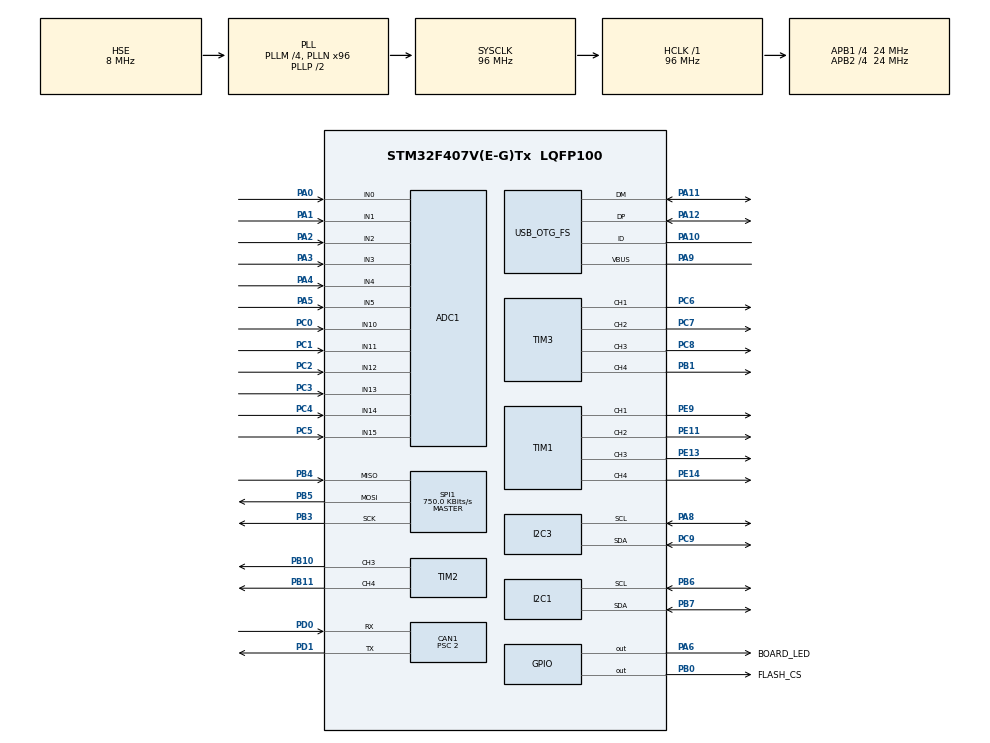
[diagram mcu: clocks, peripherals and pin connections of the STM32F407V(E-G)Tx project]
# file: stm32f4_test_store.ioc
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ADC1.Channel-0\#ChannelRegularConversion=ADC_CHANNEL_0
ADC1.Channel-1\#ChannelRegularConversion=ADC_CHANNEL_0
ADC1.Channel-10\#ChannelRegularConversion=ADC_CHANNEL_0
ADC1.Channel-11\#ChannelRegularConversion=ADC_CHANNEL_0
ADC1.Channel-2\#ChannelRegularConversion=ADC_CHANNEL_0
ADC1.Channel-3\#ChannelRegularConversion=ADC_CHANNEL_0
ADC1.Channel-4\#ChannelRegularConversion=ADC_CHANNEL_0
ADC1.Channel-5\#ChannelRegularConversion=ADC_CHANNEL_0
ADC1.Channel-6\#ChannelRegularConversion=ADC_CHANNEL_0
ADC1.Channel-7\#ChannelRegularConversion=ADC_CHANNEL_0
ADC1.Channel-8\#ChannelRegularConversion=ADC_CHANNEL_0
ADC1.Channel-9\#ChannelRegularConversion=ADC_CHANNEL_0
ADC1.NbrOfConversion=12
ADC1.NbrOfConversionFlag=1
ADC1.Rank-0\#ChannelRegularConversion=1
ADC1.Rank-1\#ChannelRegularConversion=2
ADC1.Rank-10\#ChannelRegularConversion=11
ADC1.Rank-11\#ChannelRegularConversion=12
ADC1.Rank-2\#ChannelRegularConversion=3
ADC1.Rank-3\#ChannelRegularConversion=4
ADC1.Rank-4\#ChannelRegularConversion=5
ADC1.Rank-5\#ChannelRegularConversion=6
ADC1.Rank-6\#ChannelRegularConversion=7
ADC1.Rank-7\#ChannelRegularConversion=8
ADC1.Rank-8\#ChannelRegularConversion=9
ADC1.Rank-9\#ChannelRegularConversion=10
ADC1.SamplingTime-0\#ChannelRegularConversion=ADC_SAMPLETIME_3CYCLES
ADC1.SamplingTime-1\#ChannelRegularConversion=ADC_SAMPLETIME_3CYCLES
ADC1.SamplingTime-10\#ChannelRegularConversion=ADC_SAMPLETIME_3CYCLES
ADC1.SamplingTime-11\#ChannelRegularConversion=ADC_SAMPLETIME_3CYCLES
ADC1.SamplingTime-2\#ChannelRegularConversion=ADC_SAMPLETIME_3CYCLES
ADC1.SamplingTime-3\#ChannelRegularConversion=ADC_SAMPLETIME_3CYCLES
ADC1.SamplingTime-4\#ChannelRegularConversion=ADC_SAMPLETIME_3CYCLES
ADC1.SamplingTime-5\#ChannelRegularConversion=ADC_SAMPLETIME_3CYCLES
ADC1.SamplingTime-6\#ChannelRegularConversion=ADC_SAMPLETIME_3CYCLES
ADC1.SamplingTime-7\#ChannelRegularConversion=ADC_SAMPLETIME_3CYCLES
ADC1.SamplingTime-8\#ChannelRegularConversion=ADC_SAMPLETIME_3CYCLES
ADC1.SamplingTime-9\#ChannelRegularConversion=ADC_SAMPLETIME_3CYCLES
ADC1.master=1
CAN1.ABOM=ENABLE
CAN1.BS1=CAN_BS1_10TQ
CAN1.CalculateBaudRate=1000000
CAN1.CalculateTimeBit=1000
CAN1.CalculateTimeQuantum=83.33333333333333
CAN1.NART=ENABLE
CAN1.Prescaler=2
FREERTOS.HEAP_NUMBER=1
FREERTOS.INCLUDE_uxTaskPriorityGet=0
FREERTOS.INCLUDE_vTaskDelayUntil=1
FREERTOS.INCLUDE_vTaskDelete=0
FREERTOS.INCLUDE_vTaskPrioritySet=0
FREERTOS.INCLUDE_vTaskSuspend=0
FREERTOS.MEMORY_ALLOCATION=1
FREERTOS.Tasks01=oamTask,-2,128,StartOamTask,As weak,NULL,Static,oamTaskBuffer,oamTaskControlBlock
FREERTOS.configENABLE_FPU=0
FREERTOS.configIDLE_SHOULD_YIELD=0
FREERTOS.configTOTAL_HEAP_SIZE=1024
FREERTOS.configUSE_MUTEXES=0
FREERTOS.configUSE_NEWLIB_REENTRANT=0
FREERTOS.copyHeapFile=0
Mcu.Family=STM32F4
Mcu.Name=STM32F407V(E-G)Tx
Mcu.Package=LQFP100
NVIC.PriorityGroup=NVIC_PRIORITYGROUP_4
NVIC.TIM7_IRQn=true\:15\:0\:false\:false\:true\:false\:false\:true\:true
NVIC.TimeBase=TIM7_IRQn
NVIC.TimeBaseIP=TIM7
PA0-WKUP.Signal=ADCx_IN0
PA1.Signal=ADCx_IN1
PA10.Mode=OTG/Dual_Role_Device
PA10.Signal=USB_OTG_FS_ID
PA11.Mode=OTG/Dual_Role_Device
PA11.Signal=USB_OTG_FS_DM
PA12.Mode=OTG/Dual_Role_Device
PA12.Signal=USB_OTG_FS_DP
PA13.Mode=Serial_Wire
PA13.Signal=SYS_JTMS-SWDIO
PA14.Mode=Serial_Wire
PA14.Signal=SYS_JTCK-SWCLK
PA2.Signal=ADCx_IN2
PA3.Signal=ADCx_IN3
PA4.Signal=ADCx_IN4
PA5.Signal=ADCx_IN5
PA6.GPIO_Label=BOARD_LED
PA6.Signal=GPIO_Output
PA8.Mode=I2C
PA8.Signal=I2C3_SCL
PA9.Mode=Activate_VBUS
PA9.Signal=USB_OTG_FS_VBUS
PB0.GPIO_Label=FLASH_CS
PB0.Signal=GPIO_Output
PB1.Signal=S_TIM3_CH4
PB10.Signal=S_TIM2_CH3
PB11.Signal=S_TIM2_CH4
PB3.Mode=Full_Duplex_Master
PB3.Signal=SPI1_SCK
PB4.Mode=Full_Duplex_Master
PB4.Signal=SPI1_MISO
PB5.Mode=Full_Duplex_Master
PB5.Signal=SPI1_MOSI
PB6.Mode=I2C
PB6.Signal=I2C1_SCL
PB7.Mode=I2C
PB7.Signal=I2C1_SDA
PC0.Signal=ADCx_IN10
PC1.Signal=ADCx_IN11
PC14-OSC32_IN.Mode=LSE-External-Oscillator
PC14-OSC32_IN.Signal=RCC_OSC32_IN
PC15-OSC32_OUT.Mode=LSE-External-Oscillator
PC15-OSC32_OUT.Signal=RCC_OSC32_OUT
PC2.Signal=ADCx_IN12
PC3.Signal=ADCx_IN13
PC4.Signal=ADCx_IN14
PC5.Signal=ADCx_IN15
PC6.Signal=S_TIM3_CH1
PC7.Signal=S_TIM3_CH2
PC8.Signal=S_TIM3_CH3
PC9.Mode=I2C
PC9.Signal=I2C3_SDA
PD0.Mode=CAN_Activate
PD0.Signal=CAN1_RX
PD1.Mode=CAN_Activate
PD1.Signal=CAN1_TX
PE11.Signal=S_TIM1_CH2
PE13.Signal=S_TIM1_CH3
PE14.Signal=S_TIM1_CH4
PE9.Signal=S_TIM1_CH1
PH0-OSC_IN.Mode=HSE-External-Oscillator
PH0-OSC_IN.Signal=RCC_OSC_IN
PH1-OSC_OUT.Mode=HSE-External-Oscillator
PH1-OSC_OUT.Signal=RCC_OSC_OUT
ProjectManager.HeapSize=0x200
ProjectManager.StackSize=0x400
ProjectManager.TargetToolchain=STM32CubeIDE
RCC.48MHZClocksFreq_Value=48000000
RCC.AHBFreq_Value=96000000
RCC.APB1CLKDivider=RCC_HCLK_DIV4
RCC.APB1Freq_Value=24000000
RCC.APB1TimFreq_Value=48000000
RCC.APB2CLKDivider=RCC_HCLK_DIV4
RCC.APB2Freq_Value=24000000
RCC.APB2TimFreq_Value=48000000
RCC.CortexFreq_Value=96000000
RCC.HCLKFreq_Value=96000000
RCC.HSE_VALUE=8000000
RCC.HSI_VALUE=16000000
RCC.PLLM=4
RCC.PLLN=96
RCC.SYSCLKFreq_VALUE=96000000
RCC.SYSCLKSource=RCC_SYSCLKSOURCE_PLLCLK
RCC.VCOOutputFreq_Value=192000000
SH.ADCx_IN0.0=ADC1_IN0,IN0
SH.ADCx_IN1.0=ADC1_IN1,IN1
SH.ADCx_IN10.0=ADC1_IN10,IN10
SH.ADCx_IN11.0=ADC1_IN11,IN11
SH.ADCx_IN12.0=ADC1_IN12,IN12
SH.ADCx_IN13.0=ADC1_IN13,IN13
SH.ADCx_IN14.0=ADC1_IN14,IN14
SH.ADCx_IN15.0=ADC1_IN15,IN15
SH.ADCx_IN2.0=ADC1_IN2,IN2
SH.ADCx_IN3.0=ADC1_IN3,IN3
SH.ADCx_IN4.0=ADC1_IN4,IN4
SH.ADCx_IN5.0=ADC1_IN5,IN5
SH.S_TIM1_CH1.0=TIM1_CH1,PWM Generation1 CH1
SH.S_TIM1_CH2.0=TIM1_CH2,PWM Generation2 CH2
SH.S_TIM1_CH3.0=TIM1_CH3,Output Compare3 CH3
SH.S_TIM1_CH4.0=TIM1_CH4,Output Compare4 CH4
SH.S_TIM2_CH3.0=TIM2_CH3,PWM Generation3 CH3
SH.S_TIM2_CH4.0=TIM2_CH4,PWM Generation4 CH4
SH.S_TIM3_CH1.0=TIM3_CH1,PWM Generation1 CH1
SH.S_TIM3_CH2.0=TIM3_CH2,PWM Generation2 CH2
SH.S_TIM3_CH3.0=TIM3_CH3,PWM Generation3 CH3
SH.S_TIM3_CH4.0=TIM3_CH4,PWM Generation4 CH4
SPI1.BaudRatePrescaler=SPI_BAUDRATEPRESCALER_32
SPI1.CalculateBaudRate=750.0 KBits/s
SPI1.Direction=SPI_DIRECTION_2LINES
SPI1.Mode=SPI_MODE_MASTER
SPI1.VirtualType=VM_MASTER
TIM1.Channel-Output\ Compare3\ CH3=TIM_CHANNEL_3
TIM1.Channel-Output\ Compare4\ CH4=TIM_CHANNEL_4
TIM1.Channel-PWM\ Generation1\ CH1=TIM_CHANNEL_1
TIM1.Channel-PWM\ Generation2\ CH2=TIM_CHANNEL_2
TIM1.CounterMode=TIM_COUNTERMODE_CENTERALIGNED3
TIM2.Channel-PWM\ Generation3\ CH3=TIM_CHANNEL_3
TIM2.Channel-PWM\ Generation4\ CH4=TIM_CHANNEL_4
TIM2.CounterMode=TIM_COUNTERMODE_CENTERALIGNED3
TIM3.Channel-PWM\ Generation1\ CH1=TIM_CHANNEL_1
TIM3.Channel-PWM\ Generation2\ CH2=TIM_CHANNEL_2
TIM3.Channel-PWM\ Generation3\ CH3=TIM_CHANNEL_3
TIM3.Channel-PWM\ Generation4\ CH4=TIM_CHANNEL_4
TIM3.CounterMode=TIM_COUNTERMODE_CENTERALIGNED3
VP_FREERTOS_VS_CMSIS_V1.Mode=CMSIS_V1
VP_SYS_VS_tim7.Mode=TIM7
VP_TIM1_VS_ClockSourceINT.Mode=Internal
VP_TIM2_VS_ClockSourceINT.Mode=Internal
board=custom

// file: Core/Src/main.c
/* USER CODE BEGIN Header */
/**
  ******************************************************************************
  * @file           : main.c
  * @brief          : Main program body
  ******************************************************************************
  * @attention
  *
  * Copyright (c) 2022 STMicroelectronics.
  * All rights reserved.
  *
  * This software is licensed under terms that can be found in the LICENSE file
  * in the root directory of this software component.
  * If no LICENSE file comes with this software, it is provided AS-IS.
  *
  ******************************************************************************
  */
/* USER CODE END Header */
#include "main.h"
#include "cmsis_os.h"

 ADC_HandleTypeDef hadc1;

CAN_HandleTypeDef hcan1;

I2C_HandleTypeDef hi2c1;
I2C_HandleTypeDef hi2c3;

SPI_HandleTypeDef hspi1;

TIM_HandleTypeDef htim1;
TIM_HandleTypeDef htim2;
TIM_HandleTypeDef htim3;

osThreadId oamTaskHandle;
uint32_t oamTaskBuffer[ 128 ];
osStaticThreadDef_t oamTaskControlBlock;
/* USER CODE BEGIN PV */

uint32_t oamTaskBuffer[] __attribute__((section(".ccmram")));

/* USER CODE END PV */

void SystemClock_Config(void);
static void MX_GPIO_Init(void);
static void MX_SPI1_Init(void);
static void MX_ADC1_Init(void);
static void MX_I2C1_Init(void);
static void MX_I2C3_Init(void);
static void MX_TIM1_Init(void);
static void MX_TIM2_Init(void);
static void MX_TIM3_Init(void);
static void MX_CAN1_Init(void);
static void MX_USB_OTG_FS_USB_Init(void);
void StartOamTask(void const * argument);

int main(void)
{

  /* MCU Configuration--------------------------------------------------------*/

  /* Reset of all peripherals, Initializes the Flash interface and the Systick. */
  HAL_Init();

  /* Configure the system clock */
  SystemClock_Config();

  /* Initialize all configured peripherals */
  MX_GPIO_Init();
  MX_SPI1_Init();
  MX_ADC1_Init();
  MX_I2C1_Init();
  MX_I2C3_Init();
  MX_TIM1_Init();
  MX_TIM2_Init();
  MX_TIM3_Init();
  MX_CAN1_Init();
  MX_USB_OTG_FS_USB_Init();

  /* Create the thread(s) */
  /* definition and creation of oamTask */
  osThreadStaticDef(oamTask, StartOamTask, osPriorityLow, 0, 128, oamTaskBuffer, &oamTaskControlBlock);
  oamTaskHandle = osThreadCreate(osThread(oamTask), NULL);

  /* Start scheduler */
  osKernelStart();

  /* We should never get here as control is now taken by the scheduler */
  /* Infinite loop */
  while (1)
  {

  }
}

void SystemClock_Config(void)
{
  RCC_OscInitTypeDef RCC_OscInitStruct = {0};
  RCC_ClkInitTypeDef RCC_ClkInitStruct = {0};

  /** Configure the main internal regulator output voltage
  */
  __HAL_RCC_PWR_CLK_ENABLE();
  __HAL_PWR_VOLTAGESCALING_CONFIG(PWR_REGULATOR_VOLTAGE_SCALE1);

  /** Initializes the RCC Oscillators according to the specified parameters
  * in the RCC_OscInitTypeDef structure.
  */
  RCC_OscInitStruct.OscillatorType = RCC_OSCILLATORTYPE_HSE;
  RCC_OscInitStruct.HSEState = RCC_HSE_ON;
  RCC_OscInitStruct.PLL.PLLState = RCC_PLL_ON;
  RCC_OscInitStruct.PLL.PLLSource = RCC_PLLSOURCE_HSE;
  RCC_OscInitStruct.PLL.PLLM = 4;
  RCC_OscInitStruct.PLL.PLLN = 96;
  RCC_OscInitStruct.PLL.PLLP = RCC_PLLP_DIV2;
  RCC_OscInitStruct.PLL.PLLQ = 4;
  if (HAL_RCC_OscConfig(&RCC_OscInitStruct) != HAL_OK)
  {
    Error_Handler();
  }

  /** Initializes the CPU, AHB and APB buses clocks
  */
  RCC_ClkInitStruct.ClockType = RCC_CLOCKTYPE_HCLK|RCC_CLOCKTYPE_SYSCLK
                              |RCC_CLOCKTYPE_PCLK1|RCC_CLOCKTYPE_PCLK2;
  RCC_ClkInitStruct.SYSCLKSource = RCC_SYSCLKSOURCE_PLLCLK;
  RCC_ClkInitStruct.AHBCLKDivider = RCC_SYSCLK_DIV1;
  RCC_ClkInitStruct.APB1CLKDivider = RCC_HCLK_DIV4;
  RCC_ClkInitStruct.APB2CLKDivider = RCC_HCLK_DIV4;

  if (HAL_RCC_ClockConfig(&RCC_ClkInitStruct, FLASH_LATENCY_3) != HAL_OK)
  {
    Error_Handler();
  }
}

static void MX_ADC1_Init(void)
{

  ADC_ChannelConfTypeDef sConfig = {0};

  /** Configure the global features of the ADC (Clock, Resolution, Data Alignment and number of conversion)
  */
  hadc1.Instance = ADC1;
  hadc1.Init.ClockPrescaler = ADC_CLOCK_SYNC_PCLK_DIV2;
  hadc1.Init.Resolution = ADC_RESOLUTION_12B;
  hadc1.Init.ScanConvMode = ENABLE;
  hadc1.Init.ContinuousConvMode = DISABLE;
  hadc1.Init.DiscontinuousConvMode = DISABLE;
  hadc1.Init.ExternalTrigConvEdge = ADC_EXTERNALTRIGCONVEDGE_NONE;
  hadc1.Init.ExternalTrigConv = ADC_SOFTWARE_START;
  hadc1.Init.DataAlign = ADC_DATAALIGN_RIGHT;
  hadc1.Init.NbrOfConversion = 12;
  hadc1.Init.DMAContinuousRequests = DISABLE;
  hadc1.Init.EOCSelection = ADC_EOC_SINGLE_CONV;
  if (HAL_ADC_Init(&hadc1) != HAL_OK)
  {
    Error_Handler();
  }

  /** Configure for the selected ADC regular channel its corresponding rank in the sequencer and its sample time.
  */
  sConfig.Channel = ADC_CHANNEL_0;
  sConfig.Rank = 1;
  sConfig.SamplingTime = ADC_SAMPLETIME_3CYCLES;
  if (HAL_ADC_ConfigChannel(&hadc1, &sConfig) != HAL_OK)
  {
    Error_Handler();
  }

  /** Configure for the selected ADC regular channel its corresponding rank in the sequencer and its sample time.
  */
  sConfig.Rank = 2;
  if (HAL_ADC_ConfigChannel(&hadc1, &sConfig) != HAL_OK)
  {
    Error_Handler();
  }

  /** Configure for the selected ADC regular channel its corresponding rank in the sequencer and its sample time.
  */
  sConfig.Rank = 3;
  if (HAL_ADC_ConfigChannel(&hadc1, &sConfig) != HAL_OK)
  {
    Error_Handler();
  }

  /** Configure for the selected ADC regular channel its corresponding rank in the sequencer and its sample time.
  */
  sConfig.Rank = 4;
  if (HAL_ADC_ConfigChannel(&hadc1, &sConfig) != HAL_OK)
  {
    Error_Handler();
  }

  /** Configure for the selected ADC regular channel its corresponding rank in the sequencer and its sample time.
  */
  sConfig.Rank = 5;
  if (HAL_ADC_ConfigChannel(&hadc1, &sConfig) != HAL_OK)
  {
    Error_Handler();
  }

  /** Configure for the selected ADC regular channel its corresponding rank in the sequencer and its sample time.
  */
  sConfig.Rank = 6;
  if (HAL_ADC_ConfigChannel(&hadc1, &sConfig) != HAL_OK)
  {
    Error_Handler();
  }

  /** Configure for the selected ADC regular channel its corresponding rank in the sequencer and its sample time.
  */
  sConfig.Rank = 7;
  if (HAL_ADC_ConfigChannel(&hadc1, &sConfig) != HAL_OK)
  {
    Error_Handler();
  }

  /** Configure for the selected ADC regular channel its corresponding rank in the sequencer and its sample time.
  */
  sConfig.Rank = 8;
  if (HAL_ADC_ConfigChannel(&hadc1, &sConfig) != HAL_OK)
  {
    Error_Handler();
  }

  /** Configure for the selected ADC regular channel its corresponding rank in the sequencer and its sample time.
  */
  sConfig.Rank = 9;
  if (HAL_ADC_ConfigChannel(&hadc1, &sConfig) != HAL_OK)
  {
    Error_Handler();
  }

  /** Configure for the selected ADC regular channel its corresponding rank in the sequencer and its sample time.
  */
  sConfig.Rank = 10;
  if (HAL_ADC_ConfigChannel(&hadc1, &sConfig) != HAL_OK)
  {
    Error_Handler();
  }

  /** Configure for the selected ADC regular channel its corresponding rank in the sequencer and its sample time.
  */
  sConfig.Rank = 11;
  if (HAL_ADC_ConfigChannel(&hadc1, &sConfig) != HAL_OK)
  {
    Error_Handler();
  }

  /** Configure for the selected ADC regular channel its corresponding rank in the sequencer and its sample time.
  */
  sConfig.Rank = 12;
  if (HAL_ADC_ConfigChannel(&hadc1, &sConfig) != HAL_OK)
  {
    Error_Handler();
  }

}

static void MX_CAN1_Init(void)
{

  hcan1.Instance = CAN1;
  hcan1.Init.Prescaler = 2;
  hcan1.Init.Mode = CAN_MODE_NORMAL;
  hcan1.Init.SyncJumpWidth = CAN_SJW_1TQ;
  hcan1.Init.TimeSeg1 = CAN_BS1_10TQ;
  hcan1.Init.TimeSeg2 = CAN_BS2_1TQ;
  hcan1.Init.TimeTriggeredMode = DISABLE;
  hcan1.Init.AutoBusOff = ENABLE;
  hcan1.Init.AutoWakeUp = DISABLE;
  hcan1.Init.AutoRetransmission = ENABLE;
  hcan1.Init.ReceiveFifoLocked = DISABLE;
  hcan1.Init.TransmitFifoPriority = DISABLE;
  if (HAL_CAN_Init(&hcan1) != HAL_OK)
  {
    Error_Handler();
  }

}

static void MX_I2C1_Init(void)
{

  hi2c1.Instance = I2C1;
  hi2c1.Init.ClockSpeed = 100000;
  hi2c1.Init.DutyCycle = I2C_DUTYCYCLE_2;
  hi2c1.Init.OwnAddress1 = 0;
  hi2c1.Init.AddressingMode = I2C_ADDRESSINGMODE_7BIT;
  hi2c1.Init.DualAddressMode = I2C_DUALADDRESS_DISABLE;
  hi2c1.Init.OwnAddress2 = 0;
  hi2c1.Init.GeneralCallMode = I2C_GENERALCALL_DISABLE;
  hi2c1.Init.NoStretchMode = I2C_NOSTRETCH_DISABLE;
  if (HAL_I2C_Init(&hi2c1) != HAL_OK)
  {
    Error_Handler();
  }

}

static void MX_I2C3_Init(void)
{

  hi2c3.Instance = I2C3;
  hi2c3.Init.ClockSpeed = 100000;
  hi2c3.Init.DutyCycle = I2C_DUTYCYCLE_2;
  hi2c3.Init.OwnAddress1 = 0;
  hi2c3.Init.AddressingMode = I2C_ADDRESSINGMODE_7BIT;
  hi2c3.Init.DualAddressMode = I2C_DUALADDRESS_DISABLE;
  hi2c3.Init.OwnAddress2 = 0;
  hi2c3.Init.GeneralCallMode = I2C_GENERALCALL_DISABLE;
  hi2c3.Init.NoStretchMode = I2C_NOSTRETCH_DISABLE;
  if (HAL_I2C_Init(&hi2c3) != HAL_OK)
  {
    Error_Handler();
  }

}

static void MX_SPI1_Init(void)
{

  /* SPI1 parameter configuration*/
  hspi1.Instance = SPI1;
  hspi1.Init.Mode = SPI_MODE_MASTER;
  hspi1.Init.Direction = SPI_DIRECTION_2LINES;
  hspi1.Init.DataSize = SPI_DATASIZE_8BIT;
  hspi1.Init.CLKPolarity = SPI_POLARITY_LOW;
  hspi1.Init.CLKPhase = SPI_PHASE_1EDGE;
  hspi1.Init.NSS = SPI_NSS_SOFT;
  hspi1.Init.BaudRatePrescaler = SPI_BAUDRATEPRESCALER_32;
  hspi1.Init.FirstBit = SPI_FIRSTBIT_MSB;
  hspi1.Init.TIMode = SPI_TIMODE_DISABLE;
  hspi1.Init.CRCCalculation = SPI_CRCCALCULATION_DISABLE;
  hspi1.Init.CRCPolynomial = 10;
  if (HAL_SPI_Init(&hspi1) != HAL_OK)
  {
    Error_Handler();
  }

}

static void MX_TIM1_Init(void)
{

  TIM_ClockConfigTypeDef sClockSourceConfig = {0};
  TIM_MasterConfigTypeDef sMasterConfig = {0};
  TIM_OC_InitTypeDef sConfigOC = {0};
  TIM_BreakDeadTimeConfigTypeDef sBreakDeadTimeConfig = {0};

  htim1.Instance = TIM1;
  htim1.Init.Prescaler = 0;
  htim1.Init.CounterMode = TIM_COUNTERMODE_CENTERALIGNED3;
  htim1.Init.Period = 65535;
  htim1.Init.ClockDivision = TIM_CLOCKDIVISION_DIV1;
  htim1.Init.RepetitionCounter = 0;
  htim1.Init.AutoReloadPreload = TIM_AUTORELOAD_PRELOAD_DISABLE;
  if (HAL_TIM_Base_Init(&htim1) != HAL_OK)
  {
    Error_Handler();
  }
  sClockSourceConfig.ClockSource = TIM_CLOCKSOURCE_INTERNAL;
  if (HAL_TIM_ConfigClockSource(&htim1, &sClockSourceConfig) != HAL_OK)
  {
    Error_Handler();
  }
  if (HAL_TIM_PWM_Init(&htim1) != HAL_OK)
  {
    Error_Handler();
  }
  if (HAL_TIM_OC_Init(&htim1) != HAL_OK)
  {
    Error_Handler();
  }
  sMasterConfig.MasterOutputTrigger = TIM_TRGO_RESET;
  sMasterConfig.MasterSlaveMode = TIM_MASTERSLAVEMODE_DISABLE;
  if (HAL_TIMEx_MasterConfigSynchronization(&htim1, &sMasterConfig) != HAL_OK)
  {
    Error_Handler();
  }
  sConfigOC.OCMode = TIM_OCMODE_PWM1;
  sConfigOC.Pulse = 0;
  sConfigOC.OCPolarity = TIM_OCPOLARITY_HIGH;
  sConfigOC.OCNPolarity = TIM_OCNPOLARITY_HIGH;
  sConfigOC.OCFastMode = TIM_OCFAST_DISABLE;
  sConfigOC.OCIdleState = TIM_OCIDLESTATE_RESET;
  sConfigOC.OCNIdleState = TIM_OCNIDLESTATE_RESET;
  if (HAL_TIM_PWM_ConfigChannel(&htim1, &sConfigOC, TIM_CHANNEL_1) != HAL_OK)
  {
    Error_Handler();
  }
  if (HAL_TIM_PWM_ConfigChannel(&htim1, &sConfigOC, TIM_CHANNEL_2) != HAL_OK)
  {
    Error_Handler();
  }
  sConfigOC.OCMode = TIM_OCMODE_TIMING;
  if (HAL_TIM_OC_ConfigChannel(&htim1, &sConfigOC, TIM_CHANNEL_3) != HAL_OK)
  {
    Error_Handler();
  }
  if (HAL_TIM_OC_ConfigChannel(&htim1, &sConfigOC, TIM_CHANNEL_4) != HAL_OK)
  {
    Error_Handler();
  }
  sBreakDeadTimeConfig.OffStateRunMode = TIM_OSSR_DISABLE;
  sBreakDeadTimeConfig.OffStateIDLEMode = TIM_OSSI_DISABLE;
  sBreakDeadTimeConfig.LockLevel = TIM_LOCKLEVEL_OFF;
  sBreakDeadTimeConfig.DeadTime = 0;
  sBreakDeadTimeConfig.BreakState = TIM_BREAK_DISABLE;
  sBreakDeadTimeConfig.BreakPolarity = TIM_BREAKPOLARITY_HIGH;
  sBreakDeadTimeConfig.AutomaticOutput = TIM_AUTOMATICOUTPUT_DISABLE;
  if (HAL_TIMEx_ConfigBreakDeadTime(&htim1, &sBreakDeadTimeConfig) != HAL_OK)
  {
    Error_Handler();
  }
  HAL_TIM_MspPostInit(&htim1);

}

static void MX_TIM2_Init(void)
{

  TIM_ClockConfigTypeDef sClockSourceConfig = {0};
  TIM_MasterConfigTypeDef sMasterConfig = {0};
  TIM_OC_InitTypeDef sConfigOC = {0};

  htim2.Instance = TIM2;
  htim2.Init.Prescaler = 0;
  htim2.Init.CounterMode = TIM_COUNTERMODE_CENTERALIGNED3;
  htim2.Init.Period = 4294967295;
  htim2.Init.ClockDivision = TIM_CLOCKDIVISION_DIV1;
  htim2.Init.AutoReloadPreload = TIM_AUTORELOAD_PRELOAD_DISABLE;
  if (HAL_TIM_Base_Init(&htim2) != HAL_OK)
  {
    Error_Handler();
  }
  sClockSourceConfig.ClockSource = TIM_CLOCKSOURCE_INTERNAL;
  if (HAL_TIM_ConfigClockSource(&htim2, &sClockSourceConfig) != HAL_OK)
  {
    Error_Handler();
  }
  if (HAL_TIM_PWM_Init(&htim2) != HAL_OK)
  {
    Error_Handler();
  }
  sMasterConfig.MasterOutputTrigger = TIM_TRGO_RESET;
  sMasterConfig.MasterSlaveMode = TIM_MASTERSLAVEMODE_DISABLE;
  if (HAL_TIMEx_MasterConfigSynchronization(&htim2, &sMasterConfig) != HAL_OK)
  {
    Error_Handler();
  }
  sConfigOC.OCMode = TIM_OCMODE_PWM1;
  sConfigOC.Pulse = 0;
  sConfigOC.OCPolarity = TIM_OCPOLARITY_HIGH;
  sConfigOC.OCFastMode = TIM_OCFAST_DISABLE;
  if (HAL_TIM_PWM_ConfigChannel(&htim2, &sConfigOC, TIM_CHANNEL_3) != HAL_OK)
  {
    Error_Handler();
  }
  if (HAL_TIM_PWM_ConfigChannel(&htim2, &sConfigOC, TIM_CHANNEL_4) != HAL_OK)
  {
    Error_Handler();
  }
  HAL_TIM_MspPostInit(&htim2);

}

static void MX_TIM3_Init(void)
{

  TIM_MasterConfigTypeDef sMasterConfig = {0};
  TIM_OC_InitTypeDef sConfigOC = {0};

  htim3.Instance = TIM3;
  htim3.Init.Prescaler = 0;
  htim3.Init.CounterMode = TIM_COUNTERMODE_CENTERALIGNED3;
  htim3.Init.Period = 65535;
  htim3.Init.ClockDivision = TIM_CLOCKDIVISION_DIV1;
  htim3.Init.AutoReloadPreload = TIM_AUTORELOAD_PRELOAD_DISABLE;
  if (HAL_TIM_PWM_Init(&htim3) != HAL_OK)
  {
    Error_Handler();
  }
  sMasterConfig.MasterOutputTrigger = TIM_TRGO_RESET;
  sMasterConfig.MasterSlaveMode = TIM_MASTERSLAVEMODE_DISABLE;
  if (HAL_TIMEx_MasterConfigSynchronization(&htim3, &sMasterConfig) != HAL_OK)
  {
    Error_Handler();
  }
  sConfigOC.OCMode = TIM_OCMODE_PWM1;
  sConfigOC.Pulse = 0;
  sConfigOC.OCPolarity = TIM_OCPOLARITY_HIGH;
  sConfigOC.OCFastMode = TIM_OCFAST_DISABLE;
  if (HAL_TIM_PWM_ConfigChannel(&htim3, &sConfigOC, TIM_CHANNEL_1) != HAL_OK)
  {
    Error_Handler();
  }
  if (HAL_TIM_PWM_ConfigChannel(&htim3, &sConfigOC, TIM_CHANNEL_2) != HAL_OK)
  {
    Error_Handler();
  }
  if (HAL_TIM_PWM_ConfigChannel(&htim3, &sConfigOC, TIM_CHANNEL_3) != HAL_OK)
  {
    Error_Handler();
  }
  if (HAL_TIM_PWM_ConfigChannel(&htim3, &sConfigOC, TIM_CHANNEL_4) != HAL_OK)
  {
    Error_Handler();
  }
  HAL_TIM_MspPostInit(&htim3);

}

static void MX_USB_OTG_FS_USB_Init(void)
{

}

static void MX_GPIO_Init(void)
{
  GPIO_InitTypeDef GPIO_InitStruct = {0};

  /* GPIO Ports Clock Enable */
  __HAL_RCC_GPIOC_CLK_ENABLE();
  __HAL_RCC_GPIOH_CLK_ENABLE();
  __HAL_RCC_GPIOA_CLK_ENABLE();
  __HAL_RCC_GPIOB_CLK_ENABLE();
  __HAL_RCC_GPIOE_CLK_ENABLE();
  __HAL_RCC_GPIOD_CLK_ENABLE();

  /*Configure GPIO pin Output Level */
  HAL_GPIO_WritePin(BOARD_LED_GPIO_Port, BOARD_LED_Pin, GPIO_PIN_RESET);

  /*Configure GPIO pin Output Level */
  HAL_GPIO_WritePin(FLASH_CS_GPIO_Port, FLASH_CS_Pin, GPIO_PIN_RESET);

  /*Configure GPIO pin : BOARD_LED_Pin */
  GPIO_InitStruct.Pin = BOARD_LED_Pin;
  GPIO_InitStruct.Mode = GPIO_MODE_OUTPUT_PP;
  GPIO_InitStruct.Pull = GPIO_NOPULL;
  GPIO_InitStruct.Speed = GPIO_SPEED_FREQ_LOW;
  HAL_GPIO_Init(BOARD_LED_GPIO_Port, &GPIO_InitStruct);

  /*Configure GPIO pin : FLASH_CS_Pin */
  GPIO_InitStruct.Pin = FLASH_CS_Pin;
  GPIO_InitStruct.Mode = GPIO_MODE_OUTPUT_PP;
  GPIO_InitStruct.Pull = GPIO_NOPULL;
  GPIO_InitStruct.Speed = GPIO_SPEED_FREQ_LOW;
  HAL_GPIO_Init(FLASH_CS_GPIO_Port, &GPIO_InitStruct);

  /*Configure GPIO pin : PA9 */
  GPIO_InitStruct.Pin = GPIO_PIN_9;
  GPIO_InitStruct.Mode = GPIO_MODE_INPUT;
  GPIO_InitStruct.Pull = GPIO_NOPULL;
  HAL_GPIO_Init(GPIOA, &GPIO_InitStruct);

  /*Configure GPIO pins : PA10 PA11 PA12 */
  GPIO_InitStruct.Pin = GPIO_PIN_10|GPIO_PIN_11|GPIO_PIN_12;
  GPIO_InitStruct.Mode = GPIO_MODE_AF_PP;
  GPIO_InitStruct.Pull = GPIO_NOPULL;
  GPIO_InitStruct.Speed = GPIO_SPEED_FREQ_VERY_HIGH;
  GPIO_InitStruct.Alternate = GPIO_AF10_OTG_FS;
  HAL_GPIO_Init(GPIOA, &GPIO_InitStruct);

}

__weak void StartOamTask(void const * argument)
{
  /* USER CODE BEGIN 5 */
  /* Infinite loop */
	//extern w25qxx_t w25qxx;
	//int rc = W25qxx_Init();

  for(;;)
  {
    osDelay(1);
  }
  /* USER CODE END 5 */
}

void HAL_TIM_PeriodElapsedCallback(TIM_HandleTypeDef *htim)
{
  if (htim->Instance == TIM7) {
    HAL_IncTick();
  }
}

void Error_Handler(void)
{
  __disable_irq();
  while (1)
  {
  }
}
